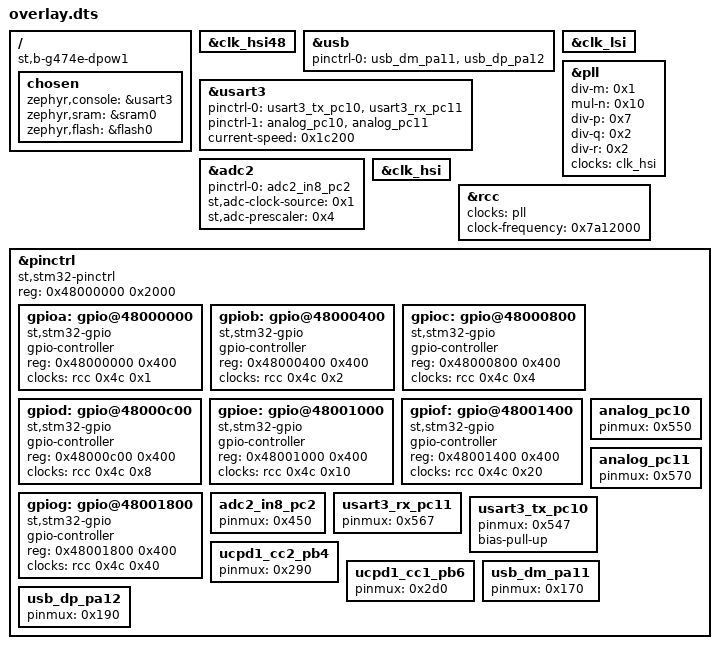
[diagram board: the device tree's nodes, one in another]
/ {
	compatible = "st,b-g474e-dpow1";
	chosen {
		zephyr,console = &usart3;
		zephyr,sram = &sram0;
		zephyr,flash = &flash0;
	};
};
&clk_hsi48{
	status = "okay";
};
&usb{
	status = "okay";
	pinctrl-0 = < &usb_dm_pa11 &usb_dp_pa12 >;
	pinctrl-names = "default";
};
&clk_lsi{
	status = "okay";
};
&pll{
	status = "okay";
	div-m = < 0x1 >;
	mul-n = < 0x10 >;
	div-p = < 0x7 >;
	div-q = < 0x2 >;
	div-r = < 0x2 >;
	clocks = < &clk_hsi >;
};
&usart3{
	status = "okay";
	pinctrl-0 = < &usart3_tx_pc10 &usart3_rx_pc11 >;
	pinctrl-1 = < &analog_pc10 &analog_pc11 >;
	pinctrl-names = "default", "sleep";
	current-speed = < 0x1c200 >;
};
&adc2{
	status = "okay";
	pinctrl-0 = < &adc2_in8_pc2 >;
	pinctrl-names = "default";
	st,adc-clock-source = < 0x1 >;
	st,adc-prescaler = < 0x4 >;
	#address-cells = < 0x1 >;
	#size-cells = < 0x0 >;
};
&clk_hsi{
	status = "okay";
};
&rcc{
	clocks = < &pll >;
	clock-frequency = < 0x7a12000 >;
};
&pinctrl{
	compatible = "st,stm32-pinctrl";
	#address-cells = < 0x1 >;
	#size-cells = < 0x1 >;
	reg = < 0x48000000 0x2000 >;
	gpioa: gpio@48000000 {
		compatible = "st,stm32-gpio";
		gpio-controller;
		#gpio-cells = < 0x2 >;
		reg = < 0x48000000 0x400 >;
		clocks = < &rcc 0x4c 0x1 >;
	};
	gpiob: gpio@48000400 {
		compatible = "st,stm32-gpio";
		gpio-controller;
		#gpio-cells = < 0x2 >;
		reg = < 0x48000400 0x400 >;
		clocks = < &rcc 0x4c 0x2 >;
	};
	gpioc: gpio@48000800 {
		compatible = "st,stm32-gpio";
		gpio-controller;
		#gpio-cells = < 0x2 >;
		reg = < 0x48000800 0x400 >;
		clocks = < &rcc 0x4c 0x4 >;
	};
	gpiod: gpio@48000c00 {
		compatible = "st,stm32-gpio";
		gpio-controller;
		#gpio-cells = < 0x2 >;
		reg = < 0x48000c00 0x400 >;
		clocks = < &rcc 0x4c 0x8 >;
	};
	gpioe: gpio@48001000 {
		compatible = "st,stm32-gpio";
		gpio-controller;
		#gpio-cells = < 0x2 >;
		reg = < 0x48001000 0x400 >;
		clocks = < &rcc 0x4c 0x10 >;
	};
	gpiof: gpio@48001400 {
		compatible = "st,stm32-gpio";
		gpio-controller;
		#gpio-cells = < 0x2 >;
		reg = < 0x48001400 0x400 >;
		clocks = < &rcc 0x4c 0x20 >;
	};
	gpiog: gpio@48001800 {
		compatible = "st,stm32-gpio";
		gpio-controller;
		#gpio-cells = < 0x2 >;
		reg = < 0x48001800 0x400 >;
		clocks = < &rcc 0x4c 0x40 >;
	};
	adc2_in8_pc2: adc2_in8_pc2 {
		pinmux = < 0x450 >;
	};
	analog_pc10: analog_pc10 {
		pinmux = < 0x550 >;
	};
	analog_pc11: analog_pc11 {
		pinmux = < 0x570 >;
	};
	usart3_rx_pc11: usart3_rx_pc11 {
		pinmux = < 0x567 >;
	};
	usart3_tx_pc10: usart3_tx_pc10 {
		pinmux = < 0x547 >;
		bias-pull-up;
	};
	ucpd1_cc2_pb4: ucpd1_cc2_pb4 {
		pinmux = < 0x290 >;
	};
	ucpd1_cc1_pb6: ucpd1_cc1_pb6 {
		pinmux = < 0x2d0 >;
	};
	usb_dm_pa11: usb_dm_pa11 {
		pinmux = < 0x170 >;
	};
	usb_dp_pa12: usb_dp_pa12 {
		pinmux = < 0x190 >;
	};
};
